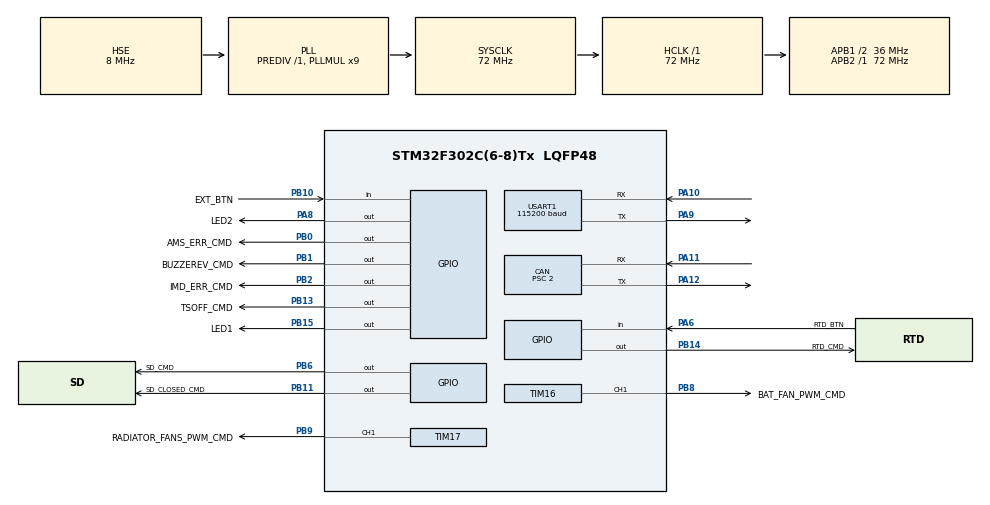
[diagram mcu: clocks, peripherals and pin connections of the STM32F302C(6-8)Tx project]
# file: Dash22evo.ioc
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CAN.ABOM=ENABLE
CAN.BS1=CAN_BS1_15TQ
CAN.BS2=CAN_BS2_2TQ
CAN.CalculateBaudRate=1000000
CAN.CalculateTimeBit=1000
CAN.CalculateTimeQuantum=55.55555555555556
CAN.Prescaler=2
CAN.SJW=CAN_SJW_1TQ
Mcu.Family=STM32F3
Mcu.Name=STM32F302C(6-8)Tx
Mcu.Package=LQFP48
NVIC.CAN_RX1_IRQn=true\:0\:0\:false\:false\:true\:true\:true\:true
NVIC.CAN_SCE_IRQn=true\:0\:0\:false\:false\:true\:true\:true\:true
NVIC.PriorityGroup=NVIC_PRIORITYGROUP_4
NVIC.TIM2_IRQn=true\:0\:0\:false\:false\:true\:true\:true\:true
NVIC.USART1_IRQn=true\:0\:0\:false\:false\:true\:true\:true\:true
NVIC.USB_LP_CAN_RX0_IRQn=true\:0\:0\:false\:false\:true\:true\:true\:true
PA10.Mode=Asynchronous
PA10.Signal=USART1_RX
PA11.Mode=CAN_Activate
PA11.Signal=CAN_RX
PA12.Mode=CAN_Activate
PA12.Signal=CAN_TX
PA13.Mode=Serial_Wire
PA13.Signal=SYS_JTMS-SWDIO
PA14.Mode=Serial_Wire
PA14.Signal=SYS_JTCK-SWCLK
PA6.GPIO_Label=RTD_BTN
PA6.GPIO_PuPd=GPIO_PULLUP
PA6.Signal=GPIO_Input
PA8.GPIO_Label=LED2
PA8.GPIO_PuPd=GPIO_PULLDOWN
PA8.PinState=GPIO_PIN_SET
PA8.Signal=GPIO_Output
PA9.Mode=Asynchronous
PA9.Signal=USART1_TX
PB0.GPIO_Label=AMS_ERR_CMD
PB0.Signal=GPIO_Output
PB1.GPIO_Label=BUZZEREV_CMD
PB1.Signal=GPIO_Output
PB10.GPIO_Label=EXT_BTN
PB10.Signal=GPIO_Input
PB11.GPIO_Label=SD_CLOSED_CMD
PB11.Signal=GPIO_Output
PB13.GPIO_Label=TSOFF_CMD
PB13.Signal=GPIO_Output
PB14.GPIO_Label=RTD_CMD
PB14.Signal=GPIO_Output
PB15.GPIO_Label=LED1
PB15.Signal=GPIO_Output
PB2.GPIO_Label=IMD_ERR_CMD
PB2.Signal=GPIO_Output
PB6.GPIO_Label=SD_CMD
PB6.Signal=GPIO_Output
PB8.GPIO_Label=BAT_FAN_PWM_CMD
PB8.Signal=S_TIM16_CH1
PB9.GPIO_Label=RADIATOR_FANS_PWM_CMD
PB9.Signal=S_TIM17_CH1
PF0-OSC_IN.Mode=HSE-External-Oscillator
PF0-OSC_IN.Signal=RCC_OSC_IN
PF1-OSC_OUT.Mode=HSE-External-Oscillator
PF1-OSC_OUT.Signal=RCC_OSC_OUT
ProjectManager.HeapSize=0x200
ProjectManager.StackSize=0x400
ProjectManager.TargetToolchain=Makefile
RCC.AHBFreq_Value=72000000
RCC.APB1CLKDivider=RCC_HCLK_DIV2
RCC.APB1Freq_Value=36000000
RCC.APB1TimFreq_Value=72000000
RCC.APB2Freq_Value=72000000
RCC.APB2TimFreq_Value=72000000
RCC.CortexFreq_Value=72000000
RCC.DATA_CACHE_ENABLE=1
RCC.HCLKFreq_Value=72000000
RCC.HSE_VALUE=8000000
RCC.HSI_VALUE=8000000
RCC.INSTRUCTION_CACHE_ENABLE=1
RCC.LSE_VALUE=32768
RCC.PLLMUL=RCC_PLL_MUL9
RCC.PLLSourceVirtual=RCC_PLLSOURCE_HSE
RCC.PWR_Regulator_Voltage_Scale=PWR_REGULATOR_VOLTAGE_SCALE2
RCC.RCC_TIM_PRescaler_Selection=RCC_TIMPRES_DESACTIVATED
RCC.SYSCLKFreq_VALUE=72000000
RCC.SYSCLKSourceVirtual=RCC_SYSCLKSOURCE_PLLCLK
RCC.USBFreq_Value=72000000
SH.S_TIM16_CH1.0=TIM16_CH1,PWM Generation1 CH1
SH.S_TIM17_CH1.0=TIM17_CH1,PWM Generation1 CH1
TIM16.Channel=TIM_CHANNEL_1
TIM16.OCMode_PWM=TIM_OCMODE_PWM2
TIM16.Period=255-1
TIM16.Prescaler=14-1
TIM17.Channel=TIM_CHANNEL_1
TIM17.OCMode_PWM=TIM_OCMODE_PWM2
TIM17.Period=255-1
TIM17.Prescaler=14-1
TIM2.Period=7200-1
USART1.BaudRate=115200
USART1.VirtualMode-Asynchronous=VM_ASYNC
VP_TIM16_VS_ClockSourceINT.Mode=Enable_Timer
VP_TIM17_VS_ClockSourceINT.Mode=Enable_Timer
VP_TIM2_VS_ClockSourceINT.Mode=Internal
board=custom

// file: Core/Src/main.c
/* USER CODE BEGIN Header */
/**
 ******************************************************************************
 * @file           : main.c
 * @brief          : Main program body
 ******************************************************************************
 * @attention
 *
 * <h2><center>&copy; Copyright (c) 2019 STMicroelectronics.
 * All rights reserved.</center></h2>
 *
 * This software component is licensed by ST under BSD 3-Clause license,
 * the "License"; You may not use this file except in compliance with the
 * License. You may obtain a copy of the License at:
 *                        opensource.org/licenses/BSD-3-Clause
 *
 ******************************************************************************
 */
/* USER CODE END Header */
#include "main.h"
#include "can.h"
#include "tim.h"
#include "usart.h"
#include "gpio.h"

/* USER CODE BEGIN Includes */
#include "dashboard.h"
#include <stdio.h>
/* USER CODE END Includes */

/* USER CODE BEGIN PV */

/*UART1 variabls*/
char msg[80] = "";
char value[60] = "";

/*CAN variables*/

/* USER CODE END PV */

void SystemClock_Config(void);

int main(void)
{

  /* MCU Configuration--------------------------------------------------------*/

  /* Reset of all peripherals, Initializes the Flash interface and the Systick. */
  HAL_Init();

  /* Configure the system clock */
  SystemClock_Config();

  /* Initialize all configured peripherals */
  MX_GPIO_Init();
  MX_USART1_UART_Init();
  MX_TIM16_Init();
  MX_TIM17_Init();
  MX_CAN_Init();
  MX_TIM2_Init();
  /* USER CODE BEGIN 2 */
    // Start the counter
    HAL_TIM_Base_Start_IT(&COUNTER_TIM);

    SetupDashBoard();

    InitDashBoard();
  /* USER CODE END 2 */

  /* Infinite loop */
    while (1)
    {

    /* USER CODE BEGIN 3 */
        CoreDashBoard();
    }
  /* USER CODE END 3 */
}

void SystemClock_Config(void)
{
  RCC_OscInitTypeDef RCC_OscInitStruct = {0};
  RCC_ClkInitTypeDef RCC_ClkInitStruct = {0};
  RCC_PeriphCLKInitTypeDef PeriphClkInit = {0};

  /** Initializes the RCC Oscillators according to the specified parameters
  * in the RCC_OscInitTypeDef structure.
  */
  RCC_OscInitStruct.OscillatorType = RCC_OSCILLATORTYPE_HSE;
  RCC_OscInitStruct.HSEState = RCC_HSE_ON;
  RCC_OscInitStruct.HSEPredivValue = RCC_HSE_PREDIV_DIV1;
  RCC_OscInitStruct.HSIState = RCC_HSI_ON;
  RCC_OscInitStruct.PLL.PLLState = RCC_PLL_ON;
  RCC_OscInitStruct.PLL.PLLSource = RCC_PLLSOURCE_HSE;
  RCC_OscInitStruct.PLL.PLLMUL = RCC_PLL_MUL9;
  if (HAL_RCC_OscConfig(&RCC_OscInitStruct) != HAL_OK)
  {
    Error_Handler();
  }

  /** Initializes the CPU, AHB and APB buses clocks
  */
  RCC_ClkInitStruct.ClockType = RCC_CLOCKTYPE_HCLK|RCC_CLOCKTYPE_SYSCLK
                              |RCC_CLOCKTYPE_PCLK1|RCC_CLOCKTYPE_PCLK2;
  RCC_ClkInitStruct.SYSCLKSource = RCC_SYSCLKSOURCE_PLLCLK;
  RCC_ClkInitStruct.AHBCLKDivider = RCC_SYSCLK_DIV1;
  RCC_ClkInitStruct.APB1CLKDivider = RCC_HCLK_DIV2;
  RCC_ClkInitStruct.APB2CLKDivider = RCC_HCLK_DIV1;

  if (HAL_RCC_ClockConfig(&RCC_ClkInitStruct, FLASH_LATENCY_2) != HAL_OK)
  {
    Error_Handler();
  }
  PeriphClkInit.PeriphClockSelection = RCC_PERIPHCLK_USART1|RCC_PERIPHCLK_TIM16
                              |RCC_PERIPHCLK_TIM17;
  PeriphClkInit.Usart1ClockSelection = RCC_USART1CLKSOURCE_PCLK1;
  PeriphClkInit.Tim16ClockSelection = RCC_TIM16CLK_HCLK;
  PeriphClkInit.Tim17ClockSelection = RCC_TIM17CLK_HCLK;
  if (HAL_RCCEx_PeriphCLKConfig(&PeriphClkInit) != HAL_OK)
  {
    Error_Handler();
  }
}

void Error_Handler(void)
{
  /* USER CODE BEGIN Error_Handler_Debug */
    /* User can add his own implementation to report the HAL error return state */
    // HAL_GPIO_TogglePin(GPIOE, GPIO_PIN_11);
    memset(msg, 0, strlen(msg));
    sprintf(msg, "\n\rError_Handler occurs\n\r");
    HAL_UART_Transmit(&huart1, (uint8_t *)msg, 30, 20);

    HAL_GPIO_WritePin(LED1_GPIO_Port, LED1_Pin, OFF);
    HAL_GPIO_WritePin(LED2_GPIO_Port, LED2_Pin, OFF);

    while (1)
    {

        /*Do nothing*/
    }
  /* USER CODE END Error_Handler_Debug */
}
